# STM32H503 register map
File version: 1.5
CPU: CM33 r0p0, little endian, MPU, FPU, 4 interrupt priority bits
Registers are 32-bit, read-write, reset 0x0 unless marked. A register's access mark holds for its fields unless they carry their own. Offsets are from the block's base; [hi:lo] are bit positions; 'fields as' and 'values as' point back to an identical list.

## DAC — Digital to analog converter
Base 0x42028400
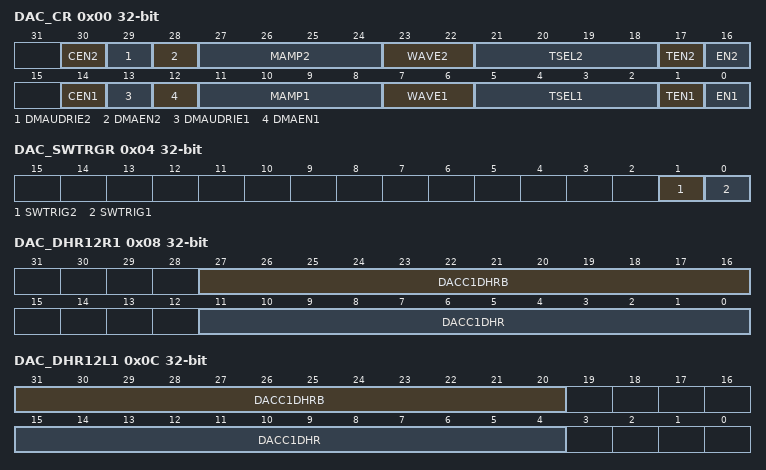
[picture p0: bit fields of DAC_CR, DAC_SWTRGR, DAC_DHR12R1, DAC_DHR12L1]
0x00 DAC_CR — DAC control register
  [30] CEN2 — DAC channel2 calibration enable This bit is set and cleared by software to enable/disable DAC channel2 calibration, it can be written only if EN2 bit is set to 0 into DAC_CR (the calibration mode can be entered/exit only when the DAC channel is disabled) Otherwise, the write operation is ignored. Note: This bit is available only on dual-channel DACs. Refer to implementation.
    0=DAC channel2 in Normal operating mode; 1=DAC channel2 in calibration mode
  [29] DMAUDRIE2 — DAC channel2 DMA underrun interrupt enable This bit is set and cleared by software. Note: This bit is available only on dual-channel DACs. Refer to implementation.
    0=DAC channel2 DMA underrun interrupt disabled; 1=DAC channel2 DMA underrun interrupt enabled
  [28] DMAEN2 — DAC channel2 DMA enable This bit is set and cleared by software. Note: This bit is available only on dual-channel DACs. Refer to implementation.
    0=DAC channel2 DMA mode disabled; 1=DAC channel2 DMA mode enabled
  [27:24] MAMP2 — DAC channel2 mask/amplitude selector These bits are written by software to select mask in wave generation mode or amplitude in triangle generation mode. greater than or equal 1011: Unmask bits[11:0] of LFSR/ triangle amplitude equal to 4095 Note: These bits are available only on dual-channel DACs. Refer to implementation.
    0=Unmask bit0 of LFSR/ triangle amplitude equal to 1; 1=Unmask bits[1:0] of LFSR/ triangle amplitude equal to 3; 2=Unmask bits[2:0] of LFSR/ triangle amplitude equal to 7; 3=Unmask bits[3:0] of LFSR/ triangle amplitude equal to 15; 4=Unmask bits[4:0] of LFSR/ triangle amplitude equal to 31; 5=Unmask bits[5:0] of LFSR/ triangle amplitude equal to 63; 6=Unmask bits[6:0] of LFSR/ triangle amplitude equal to 127; 7=Unmask bits[7:0] of LFSR/ triangle amplitude equal to 255; 8=Unmask bits[8:0] of LFSR/ triangle amplitude equal to 511; 9=Unmask bits[9:0] of LFSR/ triangle amplitude equal to 1023; 10=Unmask bits[10:0] of LFSR/ triangle amplitude equal to 2047
  [23:22] WAVE2 — DAC channel2 noise/triangle wave generation enable These bits are set/reset by software. 1x: Triangle wave generation enabled Note: Only used if bit TEN2 = 1 (DAC channel2 trigger enabled) These bits are available only on dual-channel DACs. Refer to implementation.
    0=wave generation disabled; 1=Noise wave generation enabled
  [21:18] TSEL2 — DAC channel2 trigger selection These bits select the external event used to trigger DAC channel2 ... Refer to the trigger selection tables in for details on trigger configuration and mapping. Note: Only used if bit TEN2 = 1 (DAC channel2 trigger enabled). These bits are available only on dual-channel DACs. Refer to implementation.
    0=SWTRIG2; 1=dac_ch2_trg1; 2=dac_ch2_trg2; 15=dac_ch2_trg15
  [17] TEN2 — DAC channel2 trigger enable This bit is set and cleared by software to enable/disable DAC channel2 trigger Note: When software trigger is selected, the transfer from the DAC_DHR2 register to the DAC_DOR2 register takes only one dac_hclk clock cycle. These bits are available only on dual-channel DACs. Refer to implementation.
    0=DAC channel2 trigger disabled and data written into the DAC_DHR2 register are transferred one dac_hclk clock cycle later to the DAC_DOR2 register; 1=DAC channel2 trigger enabled and data from the DAC_DHR2 register are transferred three dac_hclk clock cycles later to the DAC_DOR2 register
  [16] EN2 — DAC channel2 enable This bit is set and cleared by software to enable/disable DAC channel2. Note: These bits are available only on dual-channel DACs. Refer to implementation.
    0=DAC channel2 disabled; 1=DAC channel2 enabled
  [14] CEN1 — DAC channel1 calibration enable This bit is set and cleared by software to enable/disable DAC channel1 calibration, it can be written only if bit EN1 = 0 into DAC_CR (the calibration mode can be entered/exit only when the DAC channel is disabled) Otherwise, the write operation is ignored.
    0=DAC channel1 in Normal operating mode; 1=DAC channel1 in calibration mode
  [13] DMAUDRIE1 — DAC channel1 DMA Underrun Interrupt enable This bit is set and cleared by software.
    0=DAC channel1 DMA Underrun Interrupt disabled; 1=DAC channel1 DMA Underrun Interrupt enabled
  [12] DMAEN1 — DAC channel1 DMA enable This bit is set and cleared by software.
    0=DAC channel1 DMA mode disabled; 1=DAC channel1 DMA mode enabled
  [11:8] MAMP1 — DAC channel1 mask/amplitude selector These bits are written by software to select mask in wave generation mode or amplitude in triangle generation mode. greater than or equal 1011: Unmask bits[11:0] of LFSR/ triangle amplitude equal to 4095
    values as MAMP2
  [7:6] WAVE1 — DAC channel1 noise/triangle wave generation enable These bits are set and cleared by software. 1x: Triangle wave generation enabled Only used if bit TEN1 = 1 (DAC channel1 trigger enabled).
    0=wave generation disabled; 1=Noise wave generation enabled
  [5:2] TSEL1 — DAC channel1 trigger selection These bits select the external event used to trigger DAC channel1 ... Refer to the trigger selection tables in for details on trigger configuration and mapping. Note: Only used if bit TEN1 = 1 (DAC channel1 trigger enabled).
    0=SWTRIG1; 1=dac_ch1_trg1; 2=dac_ch1_trg2; 15=dac_ch1_trg15
  [1] TEN1 — DAC channel1 trigger enable This bit is set and cleared by software to enable/disable DAC channel1 trigger. Note: When software trigger is selected, the transfer from the DAC_DHR1 register to the DAC_DOR1 register takes only one dac_hclk clock cycle.
    0=DAC channel1 trigger disabled and data written into the DAC_DHR1 register are transferred one dac_hclk clock cycle later to the DAC_DOR1 register; 1=DAC channel1 trigger enabled and data from the DAC_DHR1 register are transferred three dac_hclk clock cycles later to the DAC_DOR1 register
  [0] EN1 — DAC channel1 enable This bit is set and cleared by software to enable/disable DAC channel1.
    0=DAC channel1 disabled; 1=DAC channel1 enabled
0x04 DAC_SWTRGR wo — DAC software trigger register
  [1] SWTRIG2 — DAC channel2 software trigger This bit is set by software to trigger the DAC in software trigger mode. Note: This bit is cleared by hardware (one dac_hclk clock cycle later) once the DAC_DHR2 register value has been loaded into the DAC_DOR2 register. This bit is available only on dual-channel DACs. Refer to implementation.
    0=No trigger; 1=Trigger
  [0] SWTRIG1 — DAC channel1 software trigger This bit is set by software to trigger the DAC in software trigger mode. Note: This bit is cleared by hardware (one dac_hclk clock cycle later) once the DAC_DHR1 register value has been loaded into the DAC_DOR1 register.
    0=No trigger; 1=Trigger
0x08 DAC_DHR12R1 — DAC channel1 12-bit right-aligned data holding register
  [27:16] DACC1DHRB — DAC channel1 12-bit right-aligned data B These bits are written by software. They specify 12-bit data for DAC channel1 when the DAC operates in Double data mode.
  [11:0] DACC1DHR — DAC channel1 12-bit right-aligned data These bits are written by software. They specify 12-bit data for DAC channel1.
0x0C DAC_DHR12L1 — DAC channel1 12-bit left aligned data holding register
  [31:20] DACC1DHRB — DAC channel1 12-bit left-aligned data B These bits are written by software. They specify 12-bit data for DAC channel1 when the DAC operates in Double data mode.
  [15:4] DACC1DHR — DAC channel1 12-bit left-aligned data These bits are written by software. They specify 12-bit data for DAC channel1.
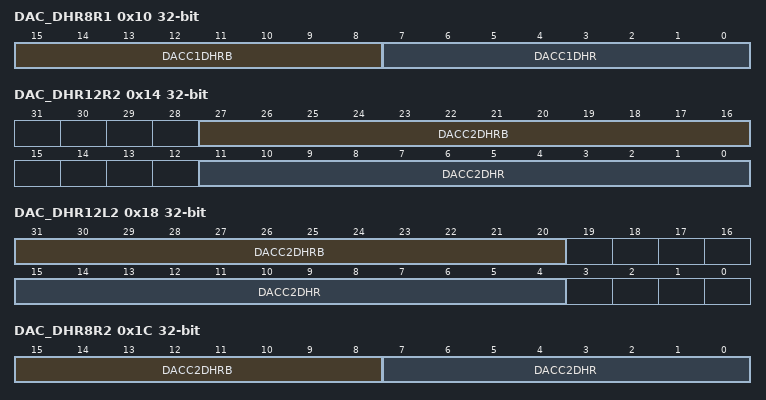
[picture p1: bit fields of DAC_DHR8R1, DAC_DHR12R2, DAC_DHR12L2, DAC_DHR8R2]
0x10 DAC_DHR8R1 — DAC channel1 8-bit right aligned data holding register
  [15:8] DACC1DHRB — DAC channel1 8-bit right-aligned data These bits are written by software. They specify 8-bit data for DAC channel1 when the DAC operates in Double data mode.
  [7:0] DACC1DHR — DAC channel1 8-bit right-aligned data These bits are written by software. They specify 8-bit data for DAC channel1.
0x14 DAC_DHR12R2 — DAC channel2 12-bit right aligned data holding register
  [27:16] DACC2DHRB — DAC channel2 12-bit right-aligned data These bits are written by software. They specify 12-bit data for DAC channel2 when the DAC operates in DMA Double data mode.
  [11:0] DACC2DHR — DAC channel2 12-bit right-aligned data These bits are written by software. They specify 12-bit data for DAC channel2.
0x18 DAC_DHR12L2 — DAC channel2 12-bit left aligned data holding register
  [31:20] DACC2DHRB — DAC channel2 12-bit left-aligned data B These bits are written by software. They specify 12-bit data for DAC channel2 when the DAC operates in Double data mode.
  [15:4] DACC2DHR — DAC channel2 12-bit left-aligned data These bits are written by software which specify 12-bit data for DAC channel2.
0x1C DAC_DHR8R2 — DAC channel2 8-bit right-aligned data holding register
  [15:8] DACC2DHRB — DAC channel2 8-bit right-aligned data These bits are written by software. They specify 8-bit data for DAC channel2 when the DAC operates in Double data mode.
  [7:0] DACC2DHR — DAC channel2 8-bit right-aligned data These bits are written by software which specifies 8-bit data for DAC channel2.
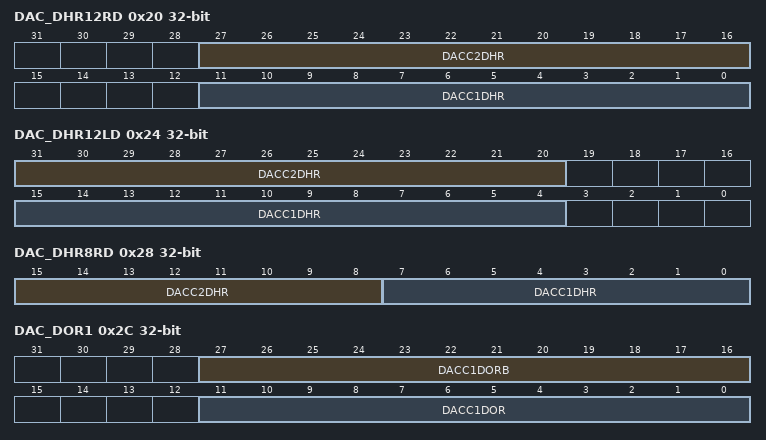
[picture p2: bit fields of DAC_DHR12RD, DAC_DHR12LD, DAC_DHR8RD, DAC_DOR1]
0x20 DAC_DHR12RD — Dual DAC 12-bit right-aligned data holding register
  [27:16] DACC2DHR — DAC channel2 12-bit right-aligned data These bits are written by software which specifies 12-bit data for DAC channel2.
  [11:0] DACC1DHR — DAC channel1 12-bit right-aligned data These bits are written by software which specifies 12-bit data for DAC channel1.
0x24 DAC_DHR12LD — Dual DAC 12-bit left aligned data holding register
  [31:20] DACC2DHR — DAC channel2 12-bit left-aligned data These bits are written by software which specifies 12-bit data for DAC channel2.
  [15:4] DACC1DHR — DAC channel1 12-bit left-aligned data These bits are written by software which specifies 12-bit data for DAC channel1.
0x28 DAC_DHR8RD — Dual DAC 8-bit right aligned data holding register
  [15:8] DACC2DHR — DAC channel2 8-bit right-aligned data These bits are written by software which specifies 8-bit data for DAC channel2.
  [7:0] DACC1DHR — DAC channel1 8-bit right-aligned data These bits are written by software which specifies 8-bit data for DAC channel1.
0x2C DAC_DOR1 ro — DAC channel1 data output register
  [27:16] DACC1DORB — DAC channel1 data output These bits are read-only. They contain data output for DAC channel1 B.
  [11:0] DACC1DOR — DAC channel1 data output These bits are read-only, they contain data output for DAC channel1.
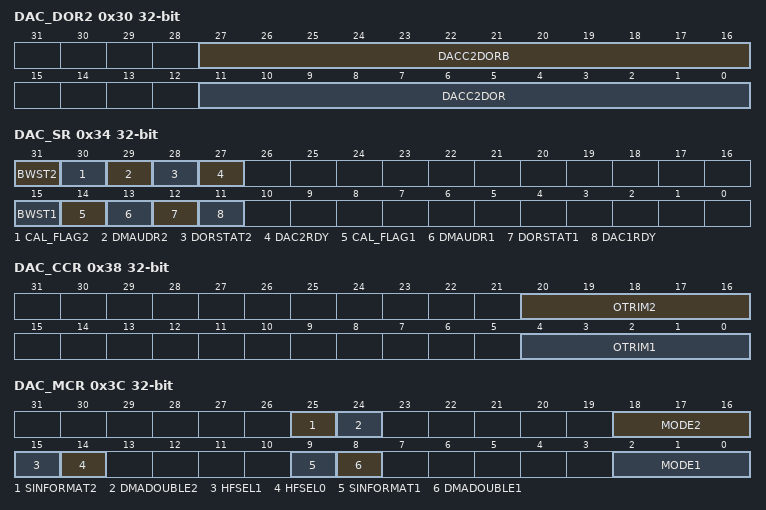
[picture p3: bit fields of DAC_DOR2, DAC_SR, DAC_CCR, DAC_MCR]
0x30 DAC_DOR2 ro — DAC channel2 data output register
  [27:16] DACC2DORB — DAC channel2 data output These bits are read-only. They contain data output for DAC channel2 B.
  [11:0] DACC2DOR — DAC channel2 data output These bits are read-only, they contain data output for DAC channel2.
0x34 DAC_SR access per field — DAC status register
  [31] BWST2 ro — DAC channel2 busy writing sample time flag This bit is systematically set just after Sample and hold mode enable. It is set each time the software writes the register DAC_SHSR2, It is cleared by hardware when the write operation of DAC_SHSR2 is complete. (It takes about 3 LSI/LSE periods of synchronization). Note: This bit is available only on dual-channel DACs. Refer to implementation.
    0=There is no write operation of DAC_SHSR2 ongoing: DAC_SHSR2 can be written; 1=There is a write operation of DAC_SHSR2 ongoing: DAC_SHSR2 cannot be written
  [30] CAL_FLAG2 ro — DAC channel2 calibration offset status This bit is set and cleared by hardware Note: This bit is available only on dual-channel DACs. Refer to implementation.
    0=calibration trimming value is lower than the offset correction value; 1=calibration trimming value is equal or greater than the offset correction value
  [29] DMAUDR2 rw — DAC channel2 DMA underrun flag This bit is set by hardware and cleared by software (by writing it to 1). Note: This bit is available only on dual-channel DACs. Refer to implementation.
    0=No DMA underrun error condition occurred for DAC channel2; 1=DMA underrun error condition occurred for DAC channel2 (the currently selected trigger is driving DAC channel2 conversion at a frequency higher than the DMA service capability rate)
  [28] DORSTAT2 ro — DAC channel2 output register status bit This bit is set and cleared by hardware. It is applicable only when the DAC operates in Double data mode. Note: This bit is available only on dual-channel DACs. Refer to implementation.
    0=DOR[11:0] is used actual DAC output; 1=DORB[11:0] is used actual DAC output
  [27] DAC2RDY ro — DAC channel2 ready status bit This bit is set and cleared by hardware. Note: This bit is available only on dual-channel DACs. Refer to implementation.
    0=DAC channel2 is not yet ready to accept the trigger nor output data; 1=DAC channel2 is ready to accept the trigger or output data
  [15] BWST1 ro — DAC channel1 busy writing sample time flag This bit is systematically set just after Sample and hold mode enable and is set each time the software writes the register DAC_SHSR1, It is cleared by hardware when the write operation of DAC_SHSR1 is complete. (It takes about 3 LSI/LSE periods of synchronization).
    0=There is no write operation of DAC_SHSR1 ongoing: DAC_SHSR1 can be written; 1=There is a write operation of DAC_SHSR1 ongoing: DAC_SHSR1 cannot be written
  [14] CAL_FLAG1 ro — DAC channel1 calibration offset status This bit is set and cleared by hardware
    values as CAL_FLAG2
  [13] DMAUDR1 rw — DAC channel1 DMA underrun flag This bit is set by hardware and cleared by software (by writing it to 1).
    0=No DMA underrun error condition occurred for DAC channel1; 1=DMA underrun error condition occurred for DAC channel1 (the currently selected trigger is driving DAC channel1 conversion at a frequency higher than the DMA service capability rate)
  [12] DORSTAT1 ro — DAC channel1 output register status bit This bit is set and cleared by hardware. It is applicable only when the DAC operates in Double data mode.
    values as DORSTAT2
  [11] DAC1RDY ro — DAC channel1 ready status bit This bit is set and cleared by hardware.
    0=DAC channel1 is not yet ready to accept the trigger nor output data; 1=DAC channel1 is ready to accept the trigger or output data
0x38 DAC_CCR (reset mask 0xFF00FF00) — DAC calibration control register
  [20:16] OTRIM2 — DAC channel2 offset trimming value These bits are available only on dual-channel DACs. Refer to implementation.
  [4:0] OTRIM1 — DAC channel1 offset trimming value
0x3C DAC_MCR — DAC mode control register
  [25] SINFORMAT2 — Enable signed format for DAC channel2 This bit is set and cleared by software. Note: This bit is available only on dual-channel DACs. Refer to implementation.
    0=Input data is in unsigned format; 1=Input data is in signed format (2's complement). The MSB bit represents the sign.
  [24] DMADOUBLE2 — DAC channel2 DMA double data mode This bit is set and cleared by software. Note: This bit is available only on dual-channel DACs. Refer to implementation.
    0=DMA Normal mode selected; 1=DMA Double data mode selected
  [18:16] MODE2 — DAC channel2 mode These bits can be written only when the DAC is disabled and not in the calibration mode (when bit EN2 = 0 and bit CEN2 = 0 in the DAC_CR register). If EN2 = 1 or CEN2 = 1 the write operation is ignored. They can be set and cleared by software to select the DAC channel2 mode: DAC channel2 in Normal mode DAC channel2 in Sample and hold mode Note: This register can be modified only when EN2 = 0. Refer to for the availability of DAC channel2.
    0=DAC channel2 is connected to external pin with Buffer enabled; 2=DAC channel2 is connected to external pin with buffer disabled; 4=DAC channel2 is connected to external pin with Buffer enabled; 6=DAC channel2 is connected to external pin with Buffer disabled
  [15] HFSEL1 — High frequency interface mode selection
    0=High frequency interface mode disabled; 1=High frequency interface mode compatible to AHB80 MHz enabled
  [14] HFSEL0 — High frequency interface mode selection
    values as HFSEL1
  [9] SINFORMAT1 — Enable signed format for DAC channel1 This bit is set and cleared by software.
    values as SINFORMAT2
  [8] DMADOUBLE1 — DAC channel1 DMA double data mode This bit is set and cleared by software.
    0=DMA Normal mode selected; 1=DMA Double data mode selected
  [2:0] MODE1 — DAC channel1 mode These bits can be written only when the DAC is disabled and not in the calibration mode (when bit EN1 = 0 and bit CEN1 = 0 in the DAC_CR register). If EN1 = 1 or CEN1 = 1 the write operation is ignored. They can be set and cleared by software to select the DAC channel1 mode: DAC channel1 in Normal mode DAC channel1 in sample & hold mode Note: This register can be modified only when EN1 = 0.
    0=DAC channel1 is connected to external pin with Buffer enabled; 1=DAC channel1 is connected to external pin and to on chip peripherals with Buffer enabled; 2=DAC channel1 is connected to external pin with Buffer disabled; 3=DAC channel1 is connected to on chip peripherals with Buffer disabled; 4=DAC channel1 is connected to external pin with Buffer enabled; 5=DAC channel1 is connected to external pin and to on chip peripherals with Buffer enabled; 6=DAC channel1 is connected to external pin and to on chip peripherals with Buffer disabled; 7=DAC channel1 is connected to on chip peripherals with Buffer disabled
0x40 DAC_SHSR1 — DAC channel1 sample and hold sample time register
  [9:0] TSAMPLE1 — DAC channel1 sample time (only valid in Sample and hold mode) These bits can be written when the DAC channel1 is disabled or also during normal operation. in the latter case, the write can be done only when BWST1 of DAC_SR register is low, If BWST1 = 1, the write operation is ignored.
0x44 DAC_SHSR2 — DAC channel2 sample and hold sample time register
  [9:0] TSAMPLE2 — DAC channel2 sample time (only valid in Sample and hold mode) These bits can be written when the DAC channel2 is disabled or also during normal operation. in the latter case, the write can be done only when BWST2 of DAC_SR register is low, if BWST2 = 1, the write operation is ignored.
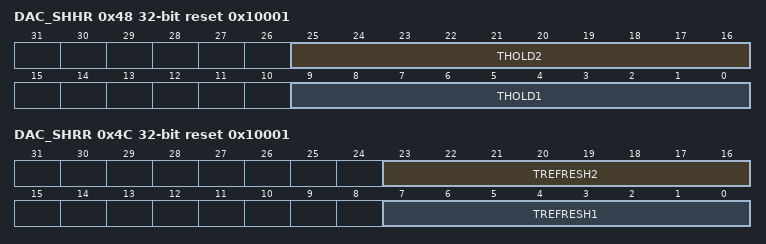
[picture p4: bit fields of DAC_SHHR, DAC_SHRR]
0x48 DAC_SHHR reset 0x10001 — DAC sample and hold time register
  [25:16] THOLD2 — DAC channel2 hold time (only valid in Sample and hold mode). Hold time = (THOLD[9:0]) x LSI/LSE clock period Note: This register can be modified only when EN2 = 0. These bits are available only on dual-channel DACs. Refer to implementation.
  [9:0] THOLD1 — DAC channel1 hold time (only valid in Sample and hold mode) Hold time = (THOLD[9:0]) x LSI/LSE clock period Note: This register can be modified only when EN1 = 0.
0x4C DAC_SHRR reset 0x10001 — DAC sample and hold refresh time register
  [23:16] TREFRESH2 — DAC channel2 refresh time (only valid in Sample and hold mode) Refresh time = (TREFRESH[7:0]) x LSI/LSE clock period Note: This register can be modified only when EN2 = 0. These bits are available only on dual-channel DACs. Refer to implementation.
  [7:0] TREFRESH1 — DAC channel1 refresh time (only valid in Sample and hold mode) Refresh time = (TREFRESH[7:0]) x LSI/LSE clock period Note: This register can be modified only when EN1 = 0.
